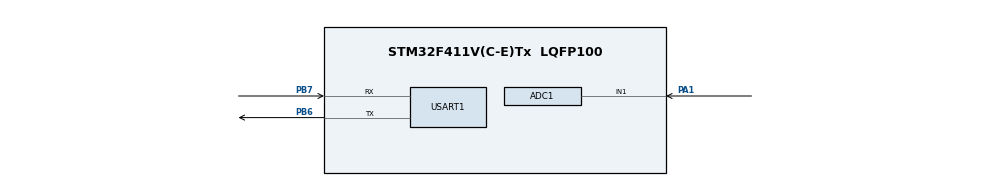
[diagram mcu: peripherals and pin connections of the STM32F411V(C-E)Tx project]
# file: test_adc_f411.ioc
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ADC1.Channel-1\#ChannelRegularConversion=ADC_CHANNEL_1
ADC1.NbrOfConversionFlag=1
ADC1.Rank-1\#ChannelRegularConversion=1
ADC1.SamplingTime-1\#ChannelRegularConversion=ADC_SAMPLETIME_3CYCLES
ADC1.master=1
Mcu.Family=STM32F4
Mcu.Name=STM32F411V(C-E)Tx
Mcu.Package=LQFP100
NVIC.PriorityGroup=NVIC_PRIORITYGROUP_4
NVIC.USART1_IRQn=true\:1\:0\:true\:false\:true\:true\:true\:true
PA1.Signal=ADCx_IN1
PA13.Mode=Serial_Wire
PA13.Signal=SYS_JTMS-SWDIO
PA14.Mode=Serial_Wire
PA14.Signal=SYS_JTCK-SWCLK
PB6.Mode=Asynchronous
PB6.Signal=USART1_TX
PB7.Mode=Asynchronous
PB7.Signal=USART1_RX
ProjectManager.HeapSize=0x200
ProjectManager.StackSize=0x400
ProjectManager.TargetToolchain=STM32CubeIDE
RCC.48MHZClocksFreq_Value=36000000
RCC.AHBCLKDivider=RCC_SYSCLK_DIV2
RCC.AHBFreq_Value=36000000
RCC.APB1Freq_Value=36000000
RCC.APB1TimFreq_Value=36000000
RCC.APB2Freq_Value=36000000
RCC.APB2TimFreq_Value=36000000
RCC.CortexFreq_Value=36000000
RCC.HCLKFreq_Value=36000000
RCC.HSE_VALUE=25000000
RCC.HSI_VALUE=16000000
RCC.LSE_VALUE=32768
RCC.PLLM=8
RCC.PLLN=72
RCC.SYSCLKFreq_VALUE=72000000
RCC.SYSCLKSource=RCC_SYSCLKSOURCE_PLLCLK
RCC.VCOOutputFreq_Value=144000000
SH.ADCx_IN1.0=ADC1_IN1,IN1
USART1.VirtualMode=VM_ASYNC
board=custom

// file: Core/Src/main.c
/* USER CODE BEGIN Header */
/**
  ******************************************************************************
  * @file           : main.c
  * @brief          : Main program body
  ******************************************************************************
  * @attention
  *
  * Copyright (c) 2024 STMicroelectronics.
  * All rights reserved.
  *
  * This software is licensed under terms that can be found in the LICENSE file
  * in the root directory of this software component.
  * If no LICENSE file comes with this software, it is provided AS-IS.
  *
  ******************************************************************************
  */
/* USER CODE END Header */
#include "main.h"

/* USER CODE BEGIN Includes */
#include "uartstdio.h"
#include <stdio.h>
/* USER CODE END Includes */

/* USER CODE BEGIN PV */

/* Variables for ADC conversion data */
__IO uint16_t uhADCxConvertedData; /* ADC group regular conversion data */

/* Variables for ADC conversion data computation to physical values */
__IO uint16_t uhADCxConvertedData_Voltage_mVolt = 0;  /* Value of voltage calculated from ADC conversion data (unit: mV) */

__IO double volt_cal = 0;
char str_send[30];

/* USER CODE END PV */

void SystemClock_Config(void);
static void MX_GPIO_Init(void);
static void MX_ADC1_Init(void);
static void MX_USART1_UART_Init(void);

/* USER CODE BEGIN 0 */
void     Activate_ADC(void);
/* USER CODE END 0 */

int main(void)
{

  /* MCU Configuration--------------------------------------------------------*/

  /* Reset of all peripherals, Initializes the Flash interface and the Systick. */
  LL_APB2_GRP1_EnableClock(LL_APB2_GRP1_PERIPH_SYSCFG);
  LL_APB1_GRP1_EnableClock(LL_APB1_GRP1_PERIPH_PWR);

  /* System interrupt init*/
  NVIC_SetPriorityGrouping(NVIC_PRIORITYGROUP_4);

  /* SysTick_IRQn interrupt configuration */
  NVIC_SetPriority(SysTick_IRQn, NVIC_EncodePriority(NVIC_GetPriorityGrouping(),15, 0));

  /* Configure the system clock */
  SystemClock_Config();

  /* Initialize all configured peripherals */
  MX_GPIO_Init();
  MX_ADC1_Init();
  MX_USART1_UART_Init();
  /* USER CODE BEGIN 2 */
	Activate_ADC();
	UARTStdioConfig(USART1,USART1_IRQn, true);
	LL_ADC_REG_StartConversionSWStart(ADC1);
  /* USER CODE END 2 */

  /* Infinite loop */
	while (1)
	{

    /* USER CODE BEGIN 3 */

	    // Wait for conversion to complete
	    if(LL_ADC_IsActiveFlag_EOCS(ADC1))
		{
			// Clear the End of Conversion flag
			LL_ADC_ClearFlag_EOCS(ADC1);

			// Read the ADC conversion result
			uhADCxConvertedData = LL_ADC_REG_ReadConversionData12(ADC1);
			UARTprintf("%d\n", uhADCxConvertedData);
			LL_ADC_REG_StartConversionSWStart(ADC1);
		}

		LL_mDelay(500);
	}
  /* USER CODE END 3 */
}

void SystemClock_Config(void)
{
  LL_FLASH_SetLatency(LL_FLASH_LATENCY_1);
  while(LL_FLASH_GetLatency()!= LL_FLASH_LATENCY_1)
  {
  }
  LL_PWR_SetRegulVoltageScaling(LL_PWR_REGU_VOLTAGE_SCALE1);
  LL_RCC_HSI_SetCalibTrimming(16);
  LL_RCC_HSI_Enable();

   /* Wait till HSI is ready */
  while(LL_RCC_HSI_IsReady() != 1)
  {

  }
  LL_RCC_PLL_ConfigDomain_SYS(LL_RCC_PLLSOURCE_HSI, LL_RCC_PLLM_DIV_8, 72, LL_RCC_PLLP_DIV_2);
  LL_RCC_PLL_Enable();

   /* Wait till PLL is ready */
  while(LL_RCC_PLL_IsReady() != 1)
  {

  }
  while (LL_PWR_IsActiveFlag_VOS() == 0)
  {
  }
  LL_RCC_SetAHBPrescaler(LL_RCC_SYSCLK_DIV_2);
  LL_RCC_SetAPB1Prescaler(LL_RCC_APB1_DIV_1);
  LL_RCC_SetAPB2Prescaler(LL_RCC_APB2_DIV_1);
  LL_RCC_SetSysClkSource(LL_RCC_SYS_CLKSOURCE_PLL);

   /* Wait till System clock is ready */
  while(LL_RCC_GetSysClkSource() != LL_RCC_SYS_CLKSOURCE_STATUS_PLL)
  {

  }
  LL_Init1msTick(36000000);
  LL_SetSystemCoreClock(36000000);
  LL_RCC_SetTIMPrescaler(LL_RCC_TIM_PRESCALER_TWICE);
}

static void MX_ADC1_Init(void)
{

  LL_ADC_InitTypeDef ADC_InitStruct = {0};
  LL_ADC_REG_InitTypeDef ADC_REG_InitStruct = {0};
  LL_ADC_CommonInitTypeDef ADC_CommonInitStruct = {0};

  LL_GPIO_InitTypeDef GPIO_InitStruct = {0};

  /* Peripheral clock enable */
  LL_APB2_GRP1_EnableClock(LL_APB2_GRP1_PERIPH_ADC1);

  LL_AHB1_GRP1_EnableClock(LL_AHB1_GRP1_PERIPH_GPIOA);
  /**ADC1 GPIO Configuration
  PA1   ------> ADC1_IN1
  */
  GPIO_InitStruct.Pin = LL_GPIO_PIN_1;
  GPIO_InitStruct.Mode = LL_GPIO_MODE_ANALOG;
  GPIO_InitStruct.Pull = LL_GPIO_PULL_NO;
  LL_GPIO_Init(GPIOA, &GPIO_InitStruct);

  /** Common config
  */
  ADC_InitStruct.Resolution = LL_ADC_RESOLUTION_12B;
  ADC_InitStruct.DataAlignment = LL_ADC_DATA_ALIGN_RIGHT;
  ADC_InitStruct.SequencersScanMode = LL_ADC_SEQ_SCAN_DISABLE;
  LL_ADC_Init(ADC1, &ADC_InitStruct);
  ADC_REG_InitStruct.TriggerSource = LL_ADC_REG_TRIG_SOFTWARE;
  ADC_REG_InitStruct.SequencerLength = LL_ADC_REG_SEQ_SCAN_DISABLE;
  ADC_REG_InitStruct.SequencerDiscont = LL_ADC_REG_SEQ_DISCONT_DISABLE;
  ADC_REG_InitStruct.ContinuousMode = LL_ADC_REG_CONV_SINGLE;
  ADC_REG_InitStruct.DMATransfer = LL_ADC_REG_DMA_TRANSFER_NONE;
  LL_ADC_REG_Init(ADC1, &ADC_REG_InitStruct);
  LL_ADC_REG_SetFlagEndOfConversion(ADC1, LL_ADC_REG_FLAG_EOC_UNITARY_CONV);
  ADC_CommonInitStruct.CommonClock = LL_ADC_CLOCK_SYNC_PCLK_DIV2;
  LL_ADC_CommonInit(__LL_ADC_COMMON_INSTANCE(ADC1), &ADC_CommonInitStruct);

  /** Configure Regular Channel
  */
  LL_ADC_REG_SetSequencerRanks(ADC1, LL_ADC_REG_RANK_1, LL_ADC_CHANNEL_1);
  LL_ADC_SetChannelSamplingTime(ADC1, LL_ADC_CHANNEL_1, LL_ADC_SAMPLINGTIME_3CYCLES);

}

static void MX_USART1_UART_Init(void)
{

  LL_USART_InitTypeDef USART_InitStruct = {0};

  LL_GPIO_InitTypeDef GPIO_InitStruct = {0};

  /* Peripheral clock enable */
  LL_APB2_GRP1_EnableClock(LL_APB2_GRP1_PERIPH_USART1);

  LL_AHB1_GRP1_EnableClock(LL_AHB1_GRP1_PERIPH_GPIOB);
  /**USART1 GPIO Configuration
  PB6   ------> USART1_TX
  PB7   ------> USART1_RX
  */
  GPIO_InitStruct.Pin = LL_GPIO_PIN_6|LL_GPIO_PIN_7;
  GPIO_InitStruct.Mode = LL_GPIO_MODE_ALTERNATE;
  GPIO_InitStruct.Speed = LL_GPIO_SPEED_FREQ_VERY_HIGH;
  GPIO_InitStruct.OutputType = LL_GPIO_OUTPUT_PUSHPULL;
  GPIO_InitStruct.Pull = LL_GPIO_PULL_NO;
  GPIO_InitStruct.Alternate = LL_GPIO_AF_7;
  LL_GPIO_Init(GPIOB, &GPIO_InitStruct);

  /* USART1 interrupt Init */
  NVIC_SetPriority(USART1_IRQn, NVIC_EncodePriority(NVIC_GetPriorityGrouping(),1, 0));
  NVIC_EnableIRQ(USART1_IRQn);

  USART_InitStruct.BaudRate = 115200;
  USART_InitStruct.DataWidth = LL_USART_DATAWIDTH_8B;
  USART_InitStruct.StopBits = LL_USART_STOPBITS_1;
  USART_InitStruct.Parity = LL_USART_PARITY_NONE;
  USART_InitStruct.TransferDirection = LL_USART_DIRECTION_TX_RX;
  USART_InitStruct.HardwareFlowControl = LL_USART_HWCONTROL_NONE;
  USART_InitStruct.OverSampling = LL_USART_OVERSAMPLING_16;
  LL_USART_Init(USART1, &USART_InitStruct);
  LL_USART_ConfigAsyncMode(USART1);
  LL_USART_Enable(USART1);

}

static void MX_GPIO_Init(void)
{

  /* GPIO Ports Clock Enable */
  LL_AHB1_GRP1_EnableClock(LL_AHB1_GRP1_PERIPH_GPIOA);
  LL_AHB1_GRP1_EnableClock(LL_AHB1_GRP1_PERIPH_GPIOB);

}

/* USER CODE BEGIN 4 */
void Activate_ADC(void)
{
	/* Enable ADC */
	LL_ADC_Enable(ADC1);
}
/* USER CODE END 4 */

void Error_Handler(void)
{
  __disable_irq();
  while (1)
  {
  }
}
